# ATBTLC1000WLCSP register map
Vendor: Atmel Corp; Series: SAMB11; File version: TODO
CPU: CM0 r0p0, little endian, no MPU, no FPU, 2 interrupt priority bits
Address unit: 32 bits
Registers are 32-bit, read-write, reset 0x0 unless marked. A register's access mark holds for its fields unless they carry their own. Offsets are from the block's base; [hi:lo] are bit positions; {n}, {i} and the like mark numbered series; 'fields as' and 'values as' point back to an identical list.

## LP_CLK_CAL_REGS0 — Low Power Clock Calibration Registers
Base 0x4000C000
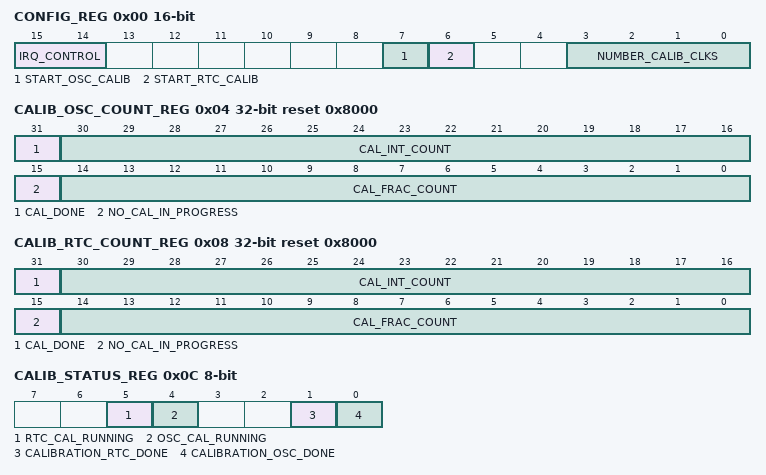
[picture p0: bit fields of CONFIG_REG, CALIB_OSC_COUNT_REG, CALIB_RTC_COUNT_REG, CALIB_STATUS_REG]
0x00 CONFIG_REG 16-bit — Configuration of the calibration clocks and the enable of calibration
  [15:14] IRQ_CONTROL — Interrupt Control
    0=IRQ when OSC calibration done; 1=IRQ when RTC calibration done; 2=IRQ when OSC or RTC calibration done; 3=IRQ when OSC and RTC calibration done
  [7] START_OSC_CALIB — If set, this will start the calibration of the OSC (32 kHz) clock
  [6] START_RTC_CALIB — If set, this will start the calibration of the RTC (32.768 kHz) clock
  [3:0] NUMBER_CALIB_CLKS — Multiplier value for the number of calibration clocks (1 shifted left by _value_)
    0=1 clock; 1=2 clocks; 2=4 clocks; 3=8 clocks; 4=16 clocks; 5=32 clocks; 6=64 clocks; 7=128 clocks; 8=256 clocks; 9=512 clocks; 10=1024 clocks; 11=2048 clocks; 12=4096 clocks; 13=8192 clocks; 14=16384 clocks; 15=32768 clocks
0x04 CALIB_OSC_COUNT_REG ro reset 0x8000 — Calibration Count register value for the OSC clock returned after completed calibration Write any value to set bit 15 and clear bit 31
  [31] CAL_DONE — Indicates calibration is done (any write clears this to a 0)
  [30:16] CAL_INT_COUNT — This is the integer part of the calibration counter
  [15] NO_CAL_IN_PROGRESS — Indicates no calibration is running (any write sets this to a 1, 0 when calibration done)
  [14:0] CAL_FRAC_COUNT — This is the fractional part of the calibration counter
0x08 CALIB_RTC_COUNT_REG ro reset 0x8000 — Calibration Count register value for the RTC clock returned after completed calibration Write any value to set bit 15 and clear bit 31
  fields as CALIB_OSC_COUNT_REG
0x0C CALIB_STATUS_REG 8-bit ro — Calibration Status Register
  [5] RTC_CAL_RUNNING — RTC clock calibration in progress
  [4] OSC_CAL_RUNNING — OSC clock calibration in progress
  [1] CALIBRATION_RTC_DONE — This is the done flag for calibrating the rtc clock
  [0] CALIBRATION_OSC_DONE — This is the done flag for calibrating the osc clock

## AON_SLEEP_TIMER0 — Always On Sleep Timer
Base 0x4000D000
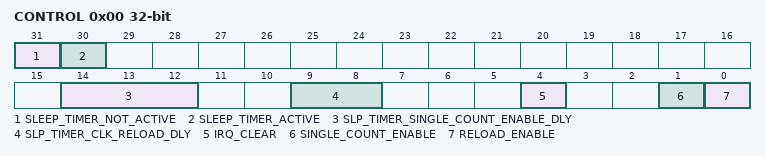
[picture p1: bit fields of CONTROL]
0x00 CONTROL — Control for the Always On Sleep Timer
  [31] SLEEP_TIMER_NOT_ACTIVE ro — If 1, indicates that the current sleep timer value is 0
  [30] SLEEP_TIMER_ACTIVE ro — If 1, indicates that the current sleep tiemr value is not 0
  [14:12] SLP_TIMER_SINGLE_COUNT_ENABLE_DLY ro — Current status of slp_timer_clk_single_count_enable on the sleep clock
  [9:8] SLP_TIMER_CLK_RELOAD_DLY ro — Current Status of slp_timer_clk_reload on the sleep clock
  [4] IRQ_CLEAR — Clears the interrupt. Auto clear. Must only be set after receiving the IRQ.
  [1] SINGLE_COUNT_ENABLE — Rising Edge Single Count Enable
  [0] RELOAD_ENABLE — Active High Reload Enable
0x04 SINGLE_COUNT_DURATION — Count for the single count AND reload
0x0C CURRENT_COUNT_VALUE ro — Current count of the sleep timer

## GPIO0 — GPIO Controller
Base 0x40010000
Same registers: GPIO1 0x40011000, GPIO2 0x40013000
0x00 DATA 16-bit — Data Value
  [15:0] VALUE — Read = Sampled at Pin : Write = To Output Data Register
0x04 DATAOUT 16-bit — Data Output Register Value
  [15:0] VALUE — Read = Current Value of Data Output Register : Write = To Output Data Register
0x10 OUTENSET 16-bit — Output Enable Set
  [15:0] VALUE — Write 1 to set the output enable bit
0x14 OUTENCLR 16-bit — Output Enable Clear
  [15:0] VALUE — Write 1 to clear the output enable bit
0x20 INTENSET 16-bit — Interrupt Enable Set
  [15:0] VALUE — Write 1 to set the enable bit
0x24 INTENCLR 16-bit — Interrupt Enable Clear
  [15:0] VALUE — Write 1 to clear the enable bit
0x28 INTTYPESET 16-bit — Interrupt Type Set
  [15:0] VALUE — Write 1 for edge
0x2C INTTYPECLR 16-bit — Interrupt Type Clear
  [15:0] VALUE — Write 1 to clear the interrupt type
0x30 INTPOLSET 16-bit — Polarity-level, edge IRQ Configuration
  [15:0] VALUE — Write 1 for HIGH level or rising edge
0x34 INTPOLCLR 16-bit — IRQ Configuration Clear
  [15:0] VALUE — Write 1 to Clear Interrupt Polarity Bit
0x38 INTSTATUSCLEAR 16-bit — Interrupt Status
  [15:0] VALUE — Write 1 to Clear Interrupt
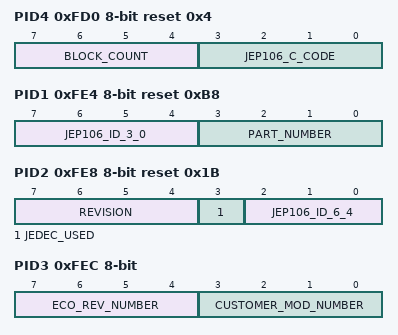
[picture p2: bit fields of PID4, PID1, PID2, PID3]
0xFD0 PID4 8-bit ro reset 0x4 — Peripheral ID Register 4
  [7:4] BLOCK_COUNT, [3:0] JEP106_C_CODE
{0xFC0+4i} PID{i} 8-bit ro (i=5..7) — Peripheral ID Register {i}
0xFE0 PID0 8-bit ro reset 0x20 — Peripheral ID Register 0
  [7:0] PART_NUMBER — Part Number Bits 7:0
0xFE4 PID1 8-bit ro reset 0xB8 — Peripheral ID Register 1
  [7:4] JEP106_ID_3_0 — JEP106 ID Bits 3:0
  [3:0] PART_NUMBER — Part Number Bits 11:8
0xFE8 PID2 8-bit ro reset 0x1B — Peripheral ID Register 2
  [7:4] REVISION
  [3] JEDEC_USED
  [2:0] JEP106_ID_6_4 — JEP106 ID Bits 6:4
0xFEC PID3 8-bit ro — Peripheral ID Register 3
  [7:4] ECO_REV_NUMBER — ECO Revision Number
  [3:0] CUSTOMER_MOD_NUMBER — Customer Modification Number
0xFF0 CID0 8-bit ro reset 0xD — Component ID Register 0
0xFF4 CID1 8-bit ro reset 0xF0 — Component ID Register 1
0xFF8 CID2 8-bit ro reset 0x5 — Component ID Register 2
0xFFC CID3 8-bit ro reset 0xB1 — Component ID Register 3
